# AT32WB415 register map
Vendor: Keil; Series: AT32WB415; File version: 1.0
CPU: CM4 r0p1, little endian, no MPU, FPU, 4 interrupt priority bits
Registers are 32-bit, read-write, reset 0x0 unless marked. A register's access mark holds for its fields unless they carry their own. Offsets are from the block's base; [hi:lo] are bit positions; {n}, {i} and the like mark numbered series.

## IOMUX — IO MUX function
Base 0x40010000
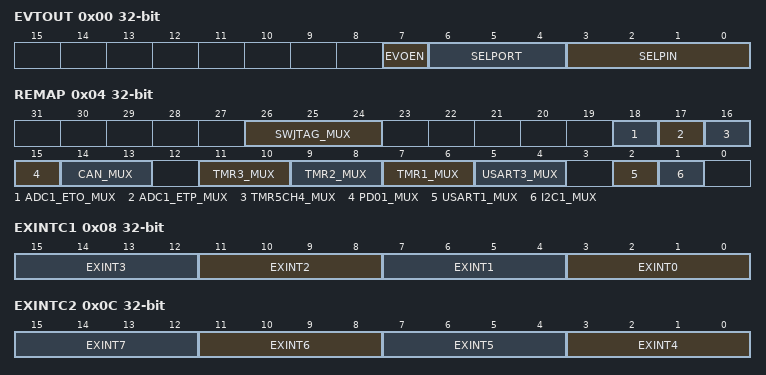
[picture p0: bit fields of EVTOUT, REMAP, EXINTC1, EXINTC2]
0x00 EVTOUT — Event output register (IOMUX_EVTOUT)
  [7] EVOEN — Event output enable
    0=Disable; 1=Enable
  [6:4] SELPORT — Select port
    0=GPIOA; 1=GPIOB; 2=GPIOC; 3=GPIOD; 6=GPIOF
  [3:0] SELPIN — Select pin
0x04 REMAP — IO MUX remap register
  [26:24] SWJTAG_MUX — SWD JTAG muxing
  [18] ADC1_ETO_MUX — ADC1 external trigger ordinary conversion muxing
  [17] ADC1_ETP_MUX — ADC1 external trigger preempted conversion muxing
  [16] TMR5CH4_MUX — TMR5 channel4 internal muxing
  [15] PD01_MUX — PD0/PD1 muxing on OSCIN/OSCOUT
  [14:13] CAN_MUX — CAN1 muxing
  [11:10] TMR3_MUX — TMR3 muxing
  [9:8] TMR2_MUX — TMR2 muxing
  [7:6] TMR1_MUX — TMR1 muxing
  [5:4] USART3_MUX — USART3 muxing
  [2] USART1_MUX — USART1 muxing
  [1] I2C1_MUX — I2C1 muxing
0x08 EXINTC1 — External interrupt configuration register 1 (IOMUX_EXINTC1)
  [4n+3:4n] EXINT{n} (n=0..3) — Configure EXINT{n} source
0x0C EXINTC2 — External interrupt configuration register 2 (IOMUX_EXINTC2)
  [4n-13:4n-16] EXINT{n} (n=4..7) — Configure EXINT{n} source
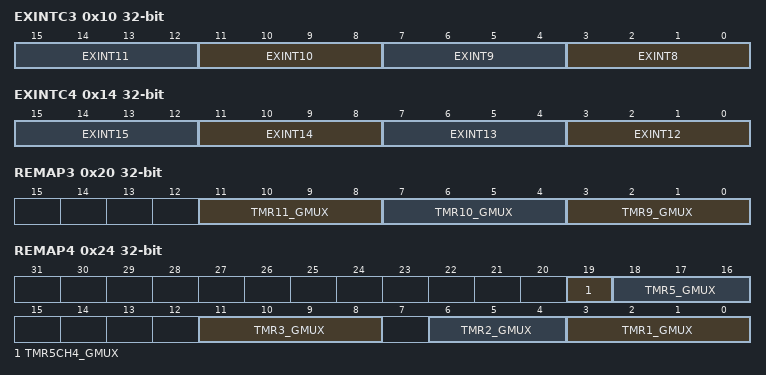
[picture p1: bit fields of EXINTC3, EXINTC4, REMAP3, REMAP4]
0x10 EXINTC3 — External interrupt configuration register 3 (IOMUX_EXINTC3)
  [4n-29:4n-32] EXINT{n} (n=8..11) — Configure EXINT{n} source
0x14 EXINTC4 — External interrupt configuration register 4 (IOMUX_EXINTC4)
  [4n-45:4n-48] EXINT{n} (n=12..15) — Configure EXINT{n} source
0x1C REMAP2 wo — IO MUX remap register 2
  [27:26] CMP_MUX — CMP internal muxing
0x20 REMAP3 — IO MUX remap register 3
  [11:8] TMR11_GMUX — TMR11 muxing
  [7:4] TMR10_GMUX — TMR10 muxing
  [3:0] TMR9_GMUX — TMR9 muxing
0x24 REMAP4 — IO MUX remap register 4
  [19] TMR5CH4_GMUX — TMR5CH4 muxing
  [18:16] TMR5_GMUX — TMR5 muxing
  [11:8] TMR3_GMUX — TMR3 muxing
  [6:4] TMR2_GMUX — TMR2 muxing
  [3:0] TMR1_GMUX — TMR1 muxing
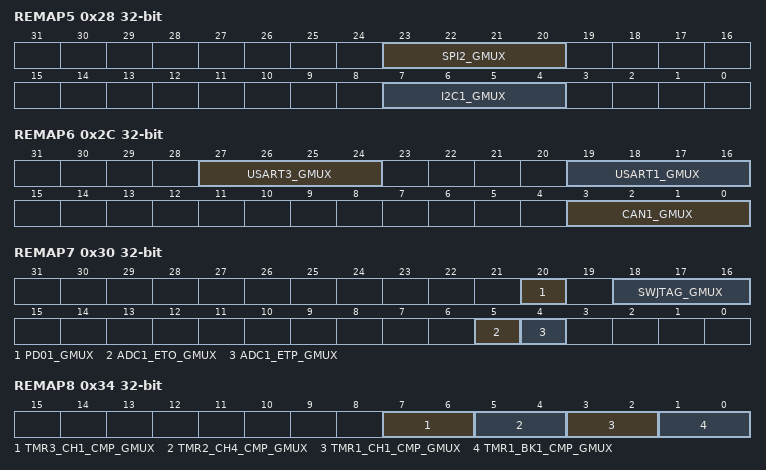
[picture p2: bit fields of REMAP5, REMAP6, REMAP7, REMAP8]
0x28 REMAP5 — IO MUX remap register 5
  [23:20] SPI2_GMUX — SPI2 muxing
  [7:4] I2C1_GMUX — I2C1 muxing
0x2C REMAP6 — IO MUX remap register 6
  [27:24] USART3_GMUX — USART3 muxing
  [19:16] USART1_GMUX — USART1 muxing
  [3:0] CAN1_GMUX — CAN1 muxing
0x30 REMAP7 — IO MUX remap register 7
  [20] PD01_GMUX — PortD0/PortD1 muxing on OSC_IN/OSC_OUT
  [18:16] SWJTAG_GMUX — Serial wire JTAG muxing
  [5] ADC1_ETO_GMUX — ADC1 external trigger ordinary conversion muxing
  [4] ADC1_ETP_GMUX — ADC1 external trigger preempted conversion muxing
0x34 REMAP8 — IO MUX remap register 8
  [7:6] TMR3_CH1_CMP_GMUX — TMR3 CH1 CMP muxing
  [5:4] TMR2_CH4_CMP_GMUX — TMR2 CH4 CMP muxing
  [3:2] TMR1_CH1_CMP_GMUX — TMR1 CH1 CMP muxing
  [1:0] TMR1_BK1_CMP_GMUX — TMR1 BK1 CMP muxing

## EXINT
Base 0x40010400
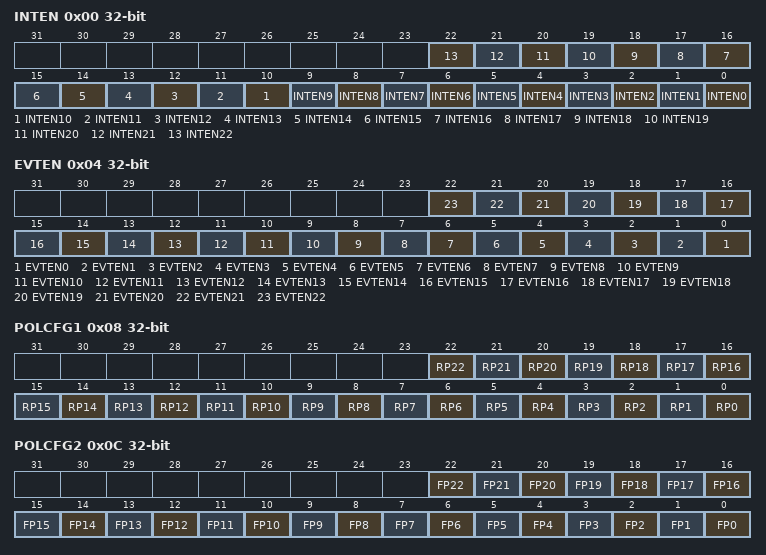
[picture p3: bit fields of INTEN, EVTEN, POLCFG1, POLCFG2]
0x00 INTEN — Interrupt enable register
  [n] INTEN{n} (n=0..22) — Interrupt enable or disable on line {n}
    on read: 0=Disabled (Interrupt request is disabled); 1=Enabled (Interrupt request is enabled) | on write: 0=Disable (Interrupt request disable); 1=Enable (Interrupt request enable)
0x04 EVTEN — Event enable register
  [n] EVTEN{n} (n=0..22) — Event enable or disable on line {n}
    on read: 0=Disabled (Event request is disabled); 1=Enabled (Event request is enabled) | on write: 0=Disable (Event request disable); 1=Enable (Event request enable)
0x08 POLCFG1 — Rising polarity configuration register
  [n] RP{n} (n=0..22) — Rising polarity configuration bit on line {n}
    on read: 0=Disabled (Rising trigger is disabled); 1=Enabled (Rising trigger is enabled) | on write: 0=Disable (Rising trigger disable); 1=Enable (Rising trigger enable)
0x0C POLCFG2 — Falling polarity configuration register
  [n] FP{n} (n=0..22) — Falling polarity configuration bit on line {n}
    on read: 0=Disabled (Falling trigger is disabled); 1=Enabled (Falling trigger is enabled) | on write: 0=Disable (Falling trigger disable); 1=Enable (Falling trigger enable)
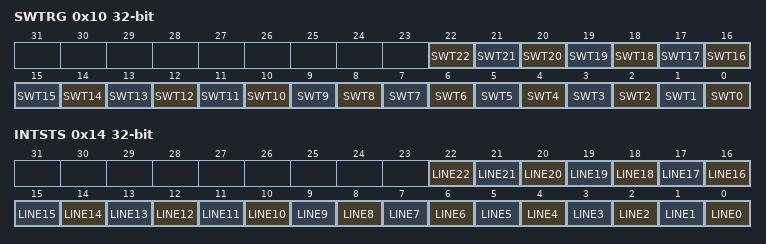
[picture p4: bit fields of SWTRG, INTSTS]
0x10 SWTRG — Software trigger register
  [n] SWT{n} (n=0..22) write-1-sets — Software trigger on line {n}
    on read: 0=NoTrigger (Default value); 1=Triggered (Software trigger generated) | on write: 1=Trigger (Generate trigger)
0x14 INTSTS — Interrupt status register
  [n] LINE{n} (n=0..22) write-1-clears — Line {n} status bit
    on read: 0=No interrupt occurred; 1=Interrupt occurred | on write: 1=Clear status flag
